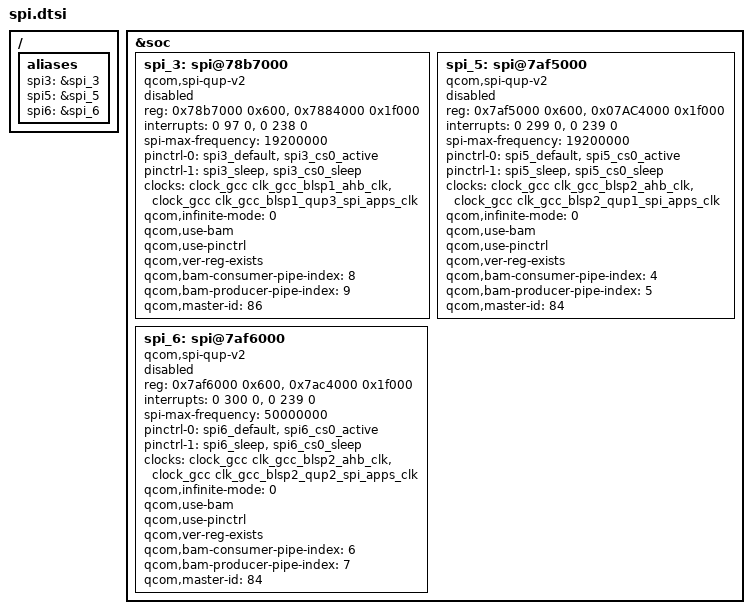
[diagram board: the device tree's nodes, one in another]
/ {
	aliases {
		spi3 = &spi_3;
		spi5 = &spi_5;
        spi6 = &spi_6;
	};
};

&soc {
    spi_3: spi@78b7000 { /* BLSP1 QUP3 */
		compatible = "qcom,spi-qup-v2";
		#address-cells = <1>;
		#size-cells = <0>;
		reg-names = "spi_physical", "spi_bam_physical";
		reg = <0x78b7000 0x600>,
			<0x7884000 0x1f000>;
		interrupt-names = "spi_irq", "spi_bam_irq";
		interrupts = <0 97 0>, <0 238 0>;
		spi-max-frequency = <19200000>;
		pinctrl-names = "spi_default", "spi_sleep";
		pinctrl-0 = <&spi3_default &spi3_cs0_active>;
		pinctrl-1 = <&spi3_sleep &spi3_cs0_sleep>;
		clocks = <&clock_gcc clk_gcc_blsp1_ahb_clk>,
			<&clock_gcc clk_gcc_blsp1_qup3_spi_apps_clk>;
		clock-names = "iface_clk", "core_clk";
		qcom,infinite-mode = <0>;
		qcom,use-bam;
		qcom,use-pinctrl;
		qcom,ver-reg-exists;
		qcom,bam-consumer-pipe-index = <8>;
		qcom,bam-producer-pipe-index = <9>;
		qcom,master-id = <86>;
		status = "disabled";
	};
	spi_5: spi@7af5000 { /* BLSP2 QUP1 */
		compatible = "qcom,spi-qup-v2";
		#address-cells = <1>;
		#size-cells = <0>;
		reg-names = "spi_physical", "spi_bam_physical";
		reg = <0x7af5000 0x600>,
			<0x07AC4000 0x1f000>;
		interrupt-names = "spi_irq", "spi_bam_irq";
		interrupts = <0 299 0>, <0 239 0>;
		spi-max-frequency = <19200000>;
		pinctrl-names = "spi_default", "spi_sleep";
		pinctrl-0 = <&spi5_default &spi5_cs0_active>;
		pinctrl-1 = <&spi5_sleep &spi5_cs0_sleep>;
		clocks = <&clock_gcc clk_gcc_blsp2_ahb_clk>,
			<&clock_gcc clk_gcc_blsp2_qup1_spi_apps_clk>;
		clock-names = "iface_clk", "core_clk";
		qcom,infinite-mode = <0>;
		qcom,use-bam;
		qcom,use-pinctrl;
		qcom,ver-reg-exists;
		qcom,bam-consumer-pipe-index = <4>;
		qcom,bam-producer-pipe-index = <5>;
		qcom,master-id = <84>;
		status = "disabled";
	};
    spi_6: spi@7af6000 { /* BLSP2 QUP2 */
		compatible = "qcom,spi-qup-v2";
		#address-cells = <1>;
		#size-cells = <0>;
		reg-names = "spi_physical", "spi_bam_physical";
		reg = <0x7af6000 0x600>,
			<0x7ac4000 0x1f000>;
		interrupt-names = "spi_irq", "spi_bam_irq";
		interrupts = <0 300 0>, <0 239 0>;
		spi-max-frequency = <50000000>;
		pinctrl-names = "spi_default", "spi_sleep";
		pinctrl-0 = <&spi6_default &spi6_cs0_active>;
		pinctrl-1 = <&spi6_sleep &spi6_cs0_sleep>;
		clocks = <&clock_gcc clk_gcc_blsp2_ahb_clk>,
			<&clock_gcc clk_gcc_blsp2_qup2_spi_apps_clk>;
		clock-names = "iface_clk", "core_clk";
		qcom,infinite-mode = <0>;
		qcom,use-bam;
		qcom,use-pinctrl;
		qcom,ver-reg-exists;
		qcom,bam-consumer-pipe-index = <6>;
		qcom,bam-producer-pipe-index = <7>;
		qcom,master-id = <84>;
		status = "disabled";
	};
};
